# RA register map
Vendor: Renesas; Series: All Chips; File version: x.xx
Registers are 32-bit, read-write, reset 0x0 unless marked. A register's access mark holds for its fields unless they carry their own. Offsets are from the block's base; [hi:lo] are bit positions; lines under a group give offsets from that group; {n}, {i} and the like mark numbered series.

## R_MPU_SPMON — CPU Stack Pointer Monitor
Base 0x40000D00
{0x0+0x10*i} SP[{i}] (i=0..1) group — Stack Pointer Monitor
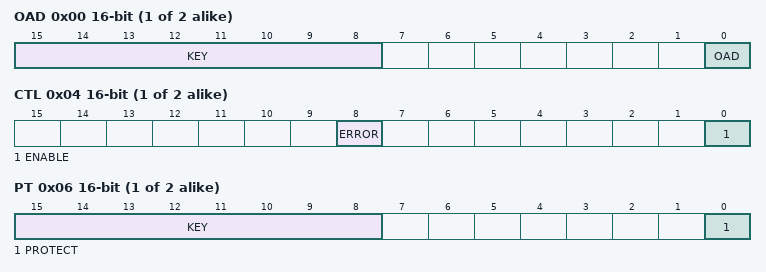
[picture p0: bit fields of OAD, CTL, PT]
  0x00 OAD 16-bit — Stack Pointer Monitor Operation After Detection Register
    [15:8] KEY wo — Write Keyword The data written to these bits are not stored.
      165=Writing to the OAD bit is valid, when the KEY bits are written 0xA5; other=others (Writing to the OAD bit is invalid.)
    [0] OAD — Operation after detection
      0=Non-maskable interrupt; 1=Reset
  0x04 CTL 16-bit (reset mask 0xFEFF) — Stack Pointer Monitor Access Control Register
    [8] ERROR — Stack Pointer Monitor Error Flag
      0=Stack pointer has not overflowed or underflowed; 1=Stack pointer has overflowed or underflowed
    [0] ENABLE — Stack Pointer Monitor Enable
      0=Stack pointer monitor is disabled; 1=Stack pointer monitor is enabled
  0x06 PT 16-bit — Stack Pointer Monitor Protection Register
    [15:8] KEY wo — Write Keyword The data written to these bits are not stored.
      165=Writing to the PROTECT bit is valid, when the KEY bits are written 0xA5; other=others (Writing to the PROTECT bit is invalid.)
    [0] PROTECT — Protection of register (MSPMPUAC, MSPMPUSA and MSPMPUSE)
      0=Stack Pointer Monitor register writing is possible; 1=Stack Pointer Monitor register writing is protected
  0x08 SA (reset mask 0x3) — Stack Pointer Monitor Start Address Register
    [31:0] MSPMPUSA range 0x1FF00000..0x200FFFFC — Region start address register Address where the region starts, for use in region determination.NOTE: Range: 0x1FF00000-0x200FFFFC The low-order 2 bits are fixed to 0.
  0x0C EA reset 0x3 (reset mask 0x3) — Stack Pointer Monitor End Address Register
    [31:0] MSPMPUEA range 0x1FF00003..0x200FFFFF — Region end address register Address where the region starts, for use in region determination.NOTE: Range: 0x1FF00003-0x200FFFFF The low-order 2 bits are fixed to 1.

## R_OPAMP — Operational Amplifier
Base 0x40086000
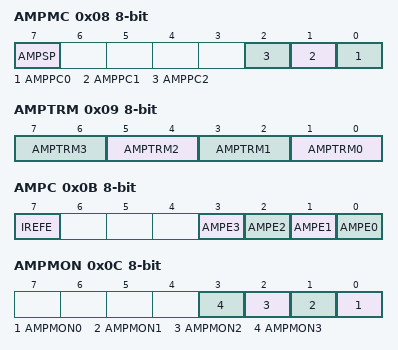
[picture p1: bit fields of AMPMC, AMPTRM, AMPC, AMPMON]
0x08 AMPMC 8-bit — Operational amplifier mode control register
  [7] AMPSP — Operation mode selection
    0=Low-power mode (low-speed); 1=High-speed mode
  [n] AMPPC{n} (n=0..2) — Operational amplifier precharge control status
    0=Precharging is stopped; 1=Precharging is enabled
0x09 AMPTRM 8-bit — Operational amplifier trigger mode control register
  [2n+1:2n] AMPTRM{n} (n=0..3) — Operational amplifier function activation/stop trigger control
    0=Software trigger mode; 1=An activation and A/D trigger mode; 2=Setting prohibited; 3=An activation and A/D trigger mode
0x0A AMPTRS 8-bit — Operational Amplifier Activation Trigger Select Register
  [1:0] AMPTRS — ELC trigger selection Do not change the value of the AMPTRS register after setting the AMPTRM register.
    0=Operational amplifier 0: Operational amplifier An activation trigger 0.Operational amplifier 1: Operational amplifier An activation trigger 1.Operational amplifier 2: Operational amplifier An activation trigger 2.Operational amplifier 3: Operational amplifier An activation trigger 3; 1=Operational amplifier 0: Operational amplifier An activation trigger 0.Operational amplifier 1: Operational amplifier An activation trigger 0.Operational amplifier 2: Operational amplifier An activation trigger 1.Operational amplifier 3: Operational amplifier An activation trigger 1; 2=Setting prohibited; 3=Operational amplifier 0: Operational amplifier An activation trigger 0.Operational amplifier 1: Operational amplifier An activation trigger 0.Operational amplifier 2: Operational amplifier An activation trigger 0.Operational amplifier 3: Operational amplifier An activation trigger 0
0x0B AMPC 8-bit — Operational amplifier control register
  [7] IREFE — Operation control of operational amplifier reference current circuit
    0=Operational amplifier reference current circuit is stopped; 1=Operation of operational amplifier reference current circuit is enabled
  [n] AMPE{n} (n=0..3) — Operation control of operational amplifier
    0=Operation amplifier is stopped; 1=Software trigger mode: Operation of operational amplifier is enabled Operation of the operational amplifier reference current circuit is also enabled regardless of the IREFE bit se An activation trigger mode or An activation and A/D trigger mode: Wait for An activation is enabled
0x0C AMPMON 8-bit ro — Operational amplifier monitor register
  [n] AMPMON{n} (n=0..3) — Operational amplifier status
    0=Operational amplifier is stopped; 1=Operational amplifier is operating
{0xE+3i} AMP[{i}] (i=0..3) group — Input and Output Selectors for Operational Amplifier {i}
  0x00 OS 8-bit — Output Select Register
  0x01 MS 8-bit — Minus Input Select Register
  0x02 PS 8-bit — Plus Input Select Register
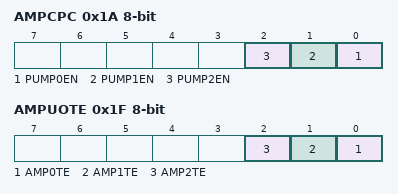
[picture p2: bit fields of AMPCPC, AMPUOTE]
0x1A AMPCPC 8-bit — Operational amplifier switch charge pump control register
  [n] PUMP{n}EN (n=0..2) — charge pump for AMP{n} enable/disable
    0=charge pump for AMP is disabled; 1=charge pump for AMP is enabled
0x1F AMPUOTE 8-bit — Operational Amplifier User Offset Trimming Enable Register
  [n] AMP{n}TE (n=0..2) — AMP{n}OT write enable
    0=Not possible to write the AMPnOTP and AMPnOTN registers; 1=Possible to write the AMPnOTP and AMPnOTN registers
{0x20+2i} AMPOT[{i}] (i=0..2) group — Operational Amplifier n Offset Trimming Registers
  0x00 P 8-bit (reset mask 0xD0) — Operational Amplifier n Offset Trimming Pch Register
    [4:0] TRMP — AMPn input offset trimming Pch side
  0x01 N 8-bit reset not defined — Operational Amplifier n Offset Trimming Nch Register
    [4:0] TRMN — AMPn input offset trimming Nch side
